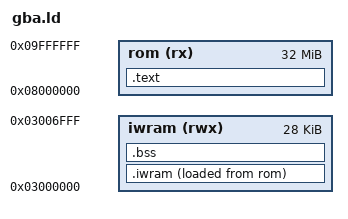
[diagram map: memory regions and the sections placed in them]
/* Linker script for the runtime test ROMs: code and constants in ROM, IWRAM sections
 * (ARM code and data) copied there by crt0, BSS in IWRAM below the stacks. */
ENTRY(_start)

MEMORY {
    rom   (rx)  : ORIGIN = 0x08000000, LENGTH = 32M
    iwram (rwx) : ORIGIN = 0x03000000, LENGTH = 0x7000
}

SECTIONS {
    .text : {
        KEEP(*(.crt0))
        *(.text .text.*)
        *(.rodata .rodata.*)
        . = ALIGN(4);
    } > rom

    .iwram : {
        __iwram_start = .;
        *(.iwram .iwram.*)
        *(.data .data.*)
        . = ALIGN(4);
        __iwram_end = .;
    } > iwram AT > rom
    __iwram_lma = LOADADDR(.iwram);

    .bss (NOLOAD) : {
        __bss_start = .;
        *(.bss .bss.* COMMON)
        . = ALIGN(4);
        __bss_end = .;
    } > iwram

    /DISCARD/ : { *(.ARM.exidx*) *(.ARM.attributes) *(.comment) }
}
